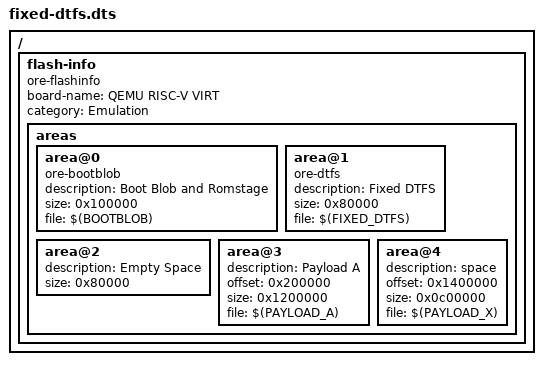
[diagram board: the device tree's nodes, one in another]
/dts-v1/;

/ {
    #address-cells = <1>;
    #size-cells = <1>;

    flash-info {
        compatible = "ore-flashinfo";
        board-name = "QEMU RISC-V VIRT";
        category = "Emulation";
        areas {
            area@0 {
                description = "Boot Blob and Romstage";
                compatible = "ore-bootblob";
                size = <0x100000>; // 1MiB
                file = "$(BOOTBLOB)";
            };
            area@1 {
                description = "Fixed DTFS";
                compatible = "ore-dtfs";
                size = <0x80000>; // 512KiB
                file = "$(FIXED_DTFS)";
            };
            area@2 {
                description = "Empty Space";
                size = <0x80000>; // 512KiB
            };
            area@3 {
                description = "Payload A";
                offset = <0x200000>;
                // TODO: reduce when support compressed payloads
                size = <0x1200000>; // 18MiB, enough for Linux + initramfs
                file = "$(PAYLOAD_A)";
            };
            area@4 {
                description = "space";
                offset = <0x1400000>;
                // TODO: reduce when support compressed payloads
                size = <0x0c00000>; // 18MiB, enough for Linux + initramfs
                file = "$(PAYLOAD_X)";
            };
        };
    };
};
